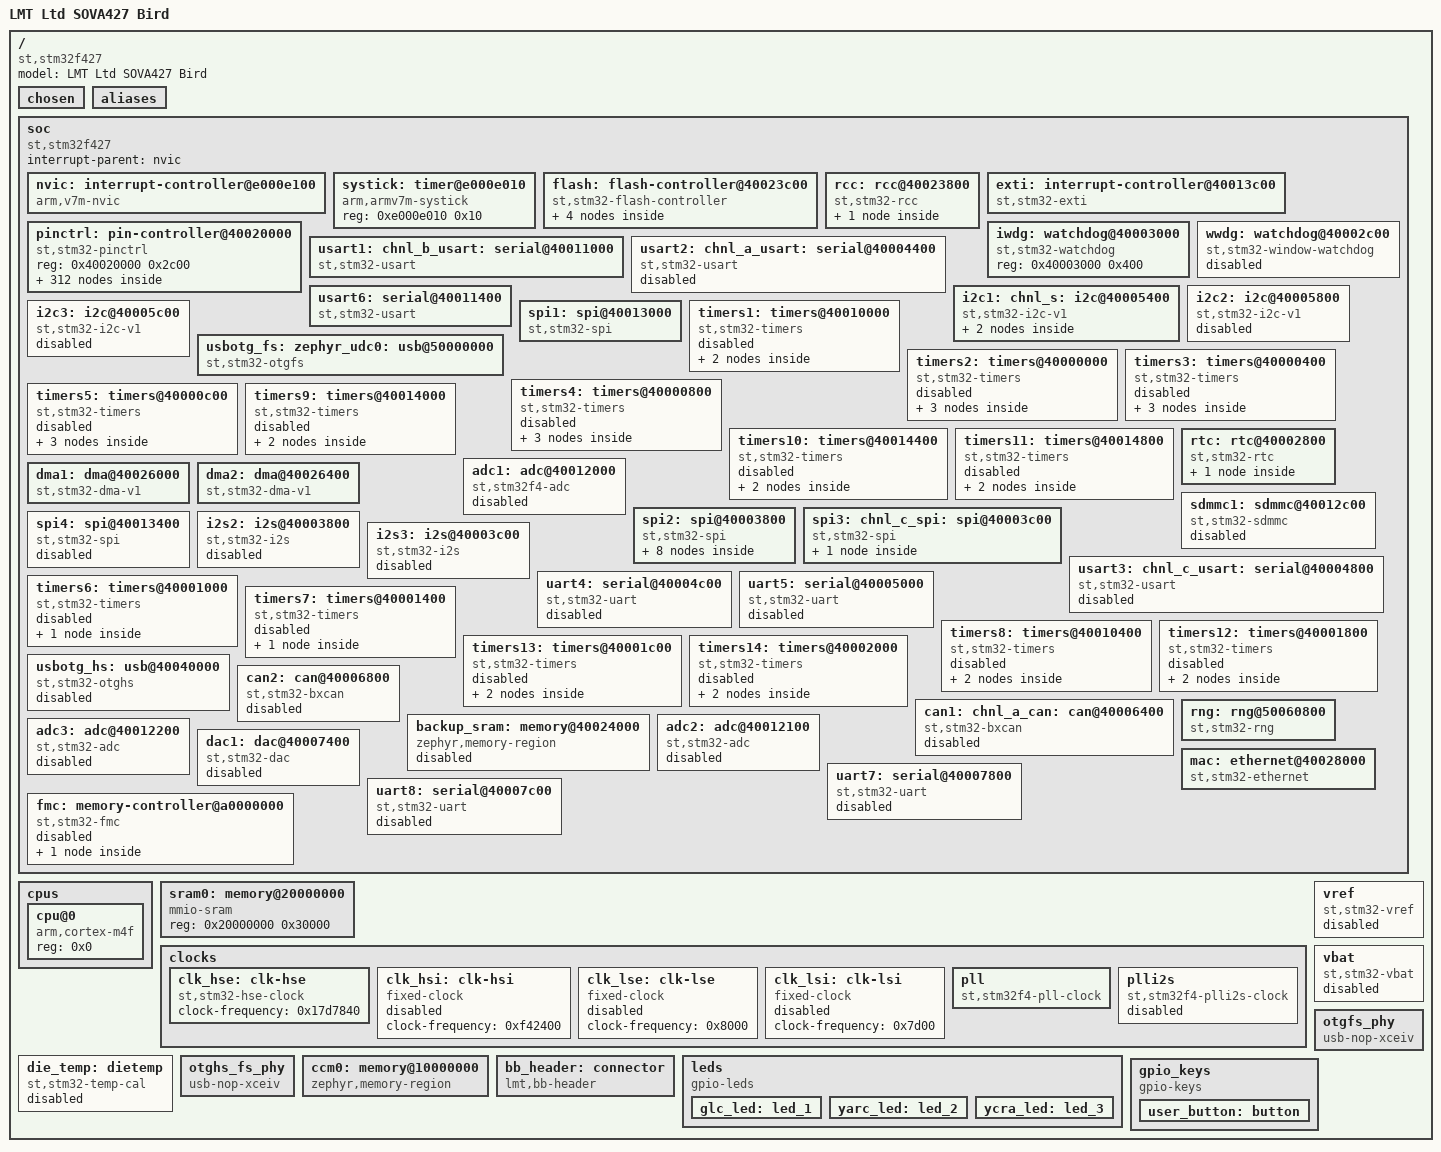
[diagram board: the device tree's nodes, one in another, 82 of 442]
/dts-v1/;

/ {
	#address-cells = < 0x1 >;
	#size-cells = < 0x1 >;
	model = "LMT Ltd SOVA427 Bird";
	compatible = "st,stm32f427";
	chosen {
		zephyr,flash-controller = &flash;
		zephyr,entropy = &rng;
		zephyr,console = &usart6;
		zephyr,shell-uart = &usart6;
		zephyr,uart-mcumgr = &usart6;
		zephyr,sram = &sram0;
		zephyr,ccm = &ccm0;
		zephyr,canbus = &can1;
		zephyr,code-partition = &slot0_partition;
		zephyr,flash = &flash0;
		zephyr,ieee802154 = &spi_cc1200;
	};
	aliases {
		led0 = &glc_led;
		led1 = &yarc_led;
		led2 = &ycra_led;
		sw0 = &user_button;
		bootloader-led0 = &glc_led;
		sdhc0 = &sdhc0;
		ti-cc1200 = &spi_cc1200;
	};
	soc {
		#address-cells = < 0x1 >;
		#size-cells = < 0x1 >;
		compatible = "st,stm32f427", "st,stm32f4", "simple-bus";
		interrupt-parent = < &nvic >;
		ranges;
		nvic: interrupt-controller@e000e100 {
			#address-cells = < 0x1 >;
			compatible = "arm,v7m-nvic";
			reg = < 0xe000e100 0xc00 >;
			interrupt-controller;
			#interrupt-cells = < 0x2 >;
			arm,num-irq-priority-bits = < 0x4 >;
			phandle = < 0x1 >;
		};
		systick: timer@e000e010 {
			compatible = "arm,armv7m-systick";
			reg = < 0xe000e010 0x10 >;
		};
		flash: flash-controller@40023c00 {
			compatible = "st,stm32-flash-controller", "st,stm32f4-flash-controller";
			reg = < 0x40023c00 0x400 >;
			interrupts = < 0x4 0x0 >;
			#address-cells = < 0x1 >;
			#size-cells = < 0x1 >;
			flash0: flash@8000000 {
				compatible = "st,stm32-nv-flash", "soc-nv-flash";
				write-block-size = < 0x1 >;
				max-erase-time = < 0xfa0 >;
				reg = < 0x8000000 0x200000 >;
				partitions {
					compatible = "fixed-partitions";
					#address-cells = < 0x1 >;
					#size-cells = < 0x1 >;
					boot_partition: partition@0 {
						label = "mcuboot";
						reg = < 0x0 0x40000 >;
						read-only;
					};
					slot0_partition: partition@40000 {
						label = "image-0";
						reg = < 0x40000 0x1c0000 >;
					};
				};
			};
		};
		rcc: rcc@40023800 {
			compatible = "st,stm32-rcc";
			#clock-cells = < 0x2 >;
			reg = < 0x40023800 0x400 >;
			clocks = < &pll >;
			clock-frequency = < 0xa037a00 >;
			ahb-prescaler = < 0x1 >;
			apb1-prescaler = < 0x4 >;
			apb2-prescaler = < 0x2 >;
			phandle = < 0x3 >;
			rctl: reset-controller {
				compatible = "st,stm32-rcc-rctl";
				#reset-cells = < 0x1 >;
				phandle = < 0x4 >;
			};
		};
		exti: interrupt-controller@40013c00 {
			compatible = "st,stm32-exti";
			interrupt-controller;
			#interrupt-cells = < 0x1 >;
			#address-cells = < 0x1 >;
			reg = < 0x40013c00 0x400 >;
			num-lines = < 0x10 >;
			interrupts = < 0x6 0x0 >, < 0x7 0x0 >, < 0x8 0x0 >, < 0x9 0x0 >, < 0xa 0x0 >, < 0x17 0x0 >, < 0x28 0x0 >;
			interrupt-names = "line0", "line1", "line2", "line3", "line4", "line5-9", "line10-15";
			line-ranges = < 0x0 0x1 >, < 0x1 0x1 >, < 0x2 0x1 >, < 0x3 0x1 >, < 0x4 0x1 >, < 0x5 0x5 >, < 0xa 0x6 >;
		};
		pinctrl: pin-controller@40020000 {
			compatible = "st,stm32-pinctrl";
			#address-cells = < 0x1 >;
			#size-cells = < 0x1 >;
			reg = < 0x40020000 0x2c00 >;
			gpioa: gpio@40020000 {
				compatible = "st,stm32-gpio";
				gpio-controller;
				#gpio-cells = < 0x2 >;
				reg = < 0x40020000 0x400 >;
				clocks = < &rcc 0x30 0x1 >;
				phandle = < 0x32 >;
			};
			gpiob: gpio@40020400 {
				compatible = "st,stm32-gpio";
				gpio-controller;
				#gpio-cells = < 0x2 >;
				reg = < 0x40020400 0x400 >;
				clocks = < &rcc 0x30 0x2 >;
				phandle = < 0x1e >;
			};
			gpioc: gpio@40020800 {
				compatible = "st,stm32-gpio";
				gpio-controller;
				#gpio-cells = < 0x2 >;
				reg = < 0x40020800 0x400 >;
				clocks = < &rcc 0x30 0x4 >;
				phandle = < 0x31 >;
			};
			gpiod: gpio@40020c00 {
				compatible = "st,stm32-gpio";
				gpio-controller;
				#gpio-cells = < 0x2 >;
				reg = < 0x40020c00 0x400 >;
				clocks = < &rcc 0x30 0x8 >;
				phandle = < 0x1d >;
			};
			gpioe: gpio@40021000 {
				compatible = "st,stm32-gpio";
				gpio-controller;
				#gpio-cells = < 0x2 >;
				reg = < 0x40021000 0x400 >;
				clocks = < &rcc 0x30 0x10 >;
				phandle = < 0x18 >;
			};
			gpiof: gpio@40021400 {
				compatible = "st,stm32-gpio";
				gpio-controller;
				#gpio-cells = < 0x2 >;
				reg = < 0x40021400 0x400 >;
				clocks = < &rcc 0x30 0x20 >;
			};
			gpiog: gpio@40021800 {
				compatible = "st,stm32-gpio";
				gpio-controller;
				#gpio-cells = < 0x2 >;
				reg = < 0x40021800 0x400 >;
				clocks = < &rcc 0x30 0x40 >;
			};
			gpioh: gpio@40021c00 {
				compatible = "st,stm32-gpio";
				gpio-controller;
				#gpio-cells = < 0x2 >;
				reg = < 0x40021c00 0x400 >;
				clocks = < &rcc 0x30 0x80 >;
			};
			gpioi: gpio@40022000 {
				compatible = "st,stm32-gpio";
				gpio-controller;
				#gpio-cells = < 0x2 >;
				reg = < 0x40022000 0x400 >;
				clocks = < &rcc 0x30 0x100 >;
			};
			gpioj: gpio@40022400 {
				compatible = "st,stm32-gpio";
				gpio-controller;
				#gpio-cells = < 0x2 >;
				reg = < 0x40022400 0x400 >;
				clocks = < &rcc 0x30 0x200 >;
			};
			gpiok: gpio@40022800 {
				compatible = "st,stm32-gpio";
				gpio-controller;
				#gpio-cells = < 0x2 >;
				reg = < 0x40022800 0x400 >;
				clocks = < &rcc 0x30 0x400 >;
			};
			adc1_in0_pa0: adc1_in0_pa0 {
				pinmux = < 0x10 >;
			};
			adc1_in1_pa1: adc1_in1_pa1 {
				pinmux = < 0x30 >;
			};
			adc1_in2_pa2: adc1_in2_pa2 {
				pinmux = < 0x50 >;
			};
			adc1_in3_pa3: adc1_in3_pa3 {
				pinmux = < 0x70 >;
			};
			adc1_in4_pa4: adc1_in4_pa4 {
				pinmux = < 0x90 >;
			};
			adc1_in5_pa5: adc1_in5_pa5 {
				pinmux = < 0xb0 >;
			};
			adc1_in6_pa6: adc1_in6_pa6 {
				pinmux = < 0xd0 >;
			};
			adc1_in7_pa7: adc1_in7_pa7 {
				pinmux = < 0xf0 >;
			};
			adc1_in8_pb0: adc1_in8_pb0 {
				pinmux = < 0x210 >;
			};
			adc1_in9_pb1: adc1_in9_pb1 {
				pinmux = < 0x230 >;
			};
			adc1_in10_pc0: adc1_in10_pc0 {
				pinmux = < 0x410 >;
			};
			adc1_in11_pc1: adc1_in11_pc1 {
				pinmux = < 0x430 >;
			};
			adc1_in12_pc2: adc1_in12_pc2 {
				pinmux = < 0x450 >;
			};
			adc1_in13_pc3: adc1_in13_pc3 {
				pinmux = < 0x470 >;
			};
			adc1_in14_pc4: adc1_in14_pc4 {
				pinmux = < 0x490 >;
			};
			adc1_in15_pc5: adc1_in15_pc5 {
				pinmux = < 0x4b0 >;
			};
			adc2_in0_pa0: adc2_in0_pa0 {
				pinmux = < 0x10 >;
			};
			adc2_in1_pa1: adc2_in1_pa1 {
				pinmux = < 0x30 >;
			};
			adc2_in2_pa2: adc2_in2_pa2 {
				pinmux = < 0x50 >;
			};
			adc2_in3_pa3: adc2_in3_pa3 {
				pinmux = < 0x70 >;
			};
			adc2_in4_pa4: adc2_in4_pa4 {
				pinmux = < 0x90 >;
			};
			adc2_in5_pa5: adc2_in5_pa5 {
				pinmux = < 0xb0 >;
			};
			adc2_in6_pa6: adc2_in6_pa6 {
				pinmux = < 0xd0 >;
			};
			adc2_in7_pa7: adc2_in7_pa7 {
				pinmux = < 0xf0 >;
			};
			adc2_in8_pb0: adc2_in8_pb0 {
				pinmux = < 0x210 >;
			};
			adc2_in9_pb1: adc2_in9_pb1 {
				pinmux = < 0x230 >;
			};
			adc2_in10_pc0: adc2_in10_pc0 {
				pinmux = < 0x410 >;
			};
			adc2_in11_pc1: adc2_in11_pc1 {
				pinmux = < 0x430 >;
			};
			adc2_in12_pc2: adc2_in12_pc2 {
				pinmux = < 0x450 >;
			};
			adc2_in13_pc3: adc2_in13_pc3 {
				pinmux = < 0x470 >;
			};
			adc2_in14_pc4: adc2_in14_pc4 {
				pinmux = < 0x490 >;
			};
			adc2_in15_pc5: adc2_in15_pc5 {
				pinmux = < 0x4b0 >;
			};
			adc3_in0_pa0: adc3_in0_pa0 {
				pinmux = < 0x10 >;
			};
			adc3_in1_pa1: adc3_in1_pa1 {
				pinmux = < 0x30 >;
			};
			adc3_in2_pa2: adc3_in2_pa2 {
				pinmux = < 0x50 >;
			};
			adc3_in3_pa3: adc3_in3_pa3 {
				pinmux = < 0x70 >;
			};
			adc3_in10_pc0: adc3_in10_pc0 {
				pinmux = < 0x410 >;
			};
			adc3_in11_pc1: adc3_in11_pc1 {
				pinmux = < 0x430 >;
			};
			adc3_in12_pc2: adc3_in12_pc2 {
				pinmux = < 0x450 >;
			};
			adc3_in13_pc3: adc3_in13_pc3 {
				pinmux = < 0x470 >;
			};
			can1_rx_pa11: can1_rx_pa11 {
				pinmux = < 0x169 >;
				bias-pull-up;
			};
			can1_rx_pb8: can1_rx_pb8 {
				pinmux = < 0x309 >;
				bias-pull-up;
			};
			can1_rx_pd0: can1_rx_pd0 {
				pinmux = < 0x609 >;
				bias-pull-up;
				phandle = < 0x24 >;
			};
			can2_rx_pb5: can2_rx_pb5 {
				pinmux = < 0x2a9 >;
				bias-pull-up;
			};
			can2_rx_pb12: can2_rx_pb12 {
				pinmux = < 0x389 >;
				bias-pull-up;
			};
			can1_tx_pa12: can1_tx_pa12 {
				pinmux = < 0x189 >;
			};
			can1_tx_pb9: can1_tx_pb9 {
				pinmux = < 0x329 >;
			};
			can1_tx_pd1: can1_tx_pd1 {
				pinmux = < 0x629 >;
				phandle = < 0x25 >;
			};
			can2_tx_pb6: can2_tx_pb6 {
				pinmux = < 0x2c9 >;
			};
			can2_tx_pb13: can2_tx_pb13 {
				pinmux = < 0x3a9 >;
			};
			dac_out1_pa4: dac_out1_pa4 {
				pinmux = < 0x90 >;
			};
			dac_out2_pa5: dac_out2_pa5 {
				pinmux = < 0xb0 >;
			};
			eth_col_pa3: eth_col_pa3 {
				pinmux = < 0x6b >;
				slew-rate = "very-high-speed";
			};
			eth_crs_pa0: eth_crs_pa0 {
				pinmux = < 0xb >;
				slew-rate = "very-high-speed";
			};
			eth_crs_dv_pa7: eth_crs_dv_pa7 {
				pinmux = < 0xeb >;
				slew-rate = "very-high-speed";
				phandle = < 0x2b >;
			};
			eth_mdc_pc1: eth_mdc_pc1 {
				pinmux = < 0x42b >;
				slew-rate = "very-high-speed";
				phandle = < 0x26 >;
			};
			eth_mdio_pa2: eth_mdio_pa2 {
				pinmux = < 0x4b >;
				slew-rate = "very-high-speed";
				phandle = < 0x2a >;
			};
			eth_pps_out_pb5: eth_pps_out_pb5 {
				pinmux = < 0x2ab >;
				slew-rate = "very-high-speed";
			};
			eth_ref_clk_pa1: eth_ref_clk_pa1 {
				pinmux = < 0x2b >;
				slew-rate = "very-high-speed";
				phandle = < 0x29 >;
			};
			eth_rxd0_pc4: eth_rxd0_pc4 {
				pinmux = < 0x48b >;
				slew-rate = "very-high-speed";
				phandle = < 0x27 >;
			};
			eth_rxd1_pc5: eth_rxd1_pc5 {
				pinmux = < 0x4ab >;
				slew-rate = "very-high-speed";
				phandle = < 0x28 >;
			};
			eth_rxd2_pb0: eth_rxd2_pb0 {
				pinmux = < 0x20b >;
				slew-rate = "very-high-speed";
			};
			eth_rxd3_pb1: eth_rxd3_pb1 {
				pinmux = < 0x22b >;
				slew-rate = "very-high-speed";
			};
			eth_rx_clk_pa1: eth_rx_clk_pa1 {
				pinmux = < 0x2b >;
				slew-rate = "very-high-speed";
			};
			eth_rx_dv_pa7: eth_rx_dv_pa7 {
				pinmux = < 0xeb >;
				slew-rate = "very-high-speed";
			};
			eth_rx_er_pb10: eth_rx_er_pb10 {
				pinmux = < 0x34b >;
				slew-rate = "very-high-speed";
			};
			eth_txd0_pb12: eth_txd0_pb12 {
				pinmux = < 0x38b >;
				slew-rate = "very-high-speed";
				phandle = < 0x2d >;
			};
			eth_txd1_pb13: eth_txd1_pb13 {
				pinmux = < 0x3ab >;
				slew-rate = "very-high-speed";
				phandle = < 0x2e >;
			};
			eth_txd2_pc2: eth_txd2_pc2 {
				pinmux = < 0x44b >;
				slew-rate = "very-high-speed";
			};
			eth_txd3_pb8: eth_txd3_pb8 {
				pinmux = < 0x30b >;
				slew-rate = "very-high-speed";
			};
			eth_txd3_pe2: eth_txd3_pe2 {
				pinmux = < 0x84b >;
				slew-rate = "very-high-speed";
			};
			eth_tx_clk_pc3: eth_tx_clk_pc3 {
				pinmux = < 0x46b >;
				slew-rate = "very-high-speed";
			};
			eth_tx_en_pb11: eth_tx_en_pb11 {
				pinmux = < 0x36b >;
				slew-rate = "very-high-speed";
				phandle = < 0x2c >;
			};
			fmc_sdcke1_pb5: fmc_sdcke1_pb5 {
				pinmux = < 0x2ac >;
				bias-pull-up;
				slew-rate = "very-high-speed";
			};
			fmc_sdne1_pb6: fmc_sdne1_pb6 {
				pinmux = < 0x2cc >;
				bias-pull-up;
				slew-rate = "very-high-speed";
			};
			fmc_nl_pb7: fmc_nl_pb7 {
				pinmux = < 0x2ec >;
				bias-pull-up;
				slew-rate = "very-high-speed";
			};
			fmc_sdnwe_pc0: fmc_sdnwe_pc0 {
				pinmux = < 0x40c >;
				bias-pull-up;
				slew-rate = "very-high-speed";
			};
			fmc_sdne0_pc2: fmc_sdne0_pc2 {
				pinmux = < 0x44c >;
				bias-pull-up;
				slew-rate = "very-high-speed";
			};
			fmc_sdcke0_pc3: fmc_sdcke0_pc3 {
				pinmux = < 0x46c >;
				bias-pull-up;
				slew-rate = "very-high-speed";
			};
			fmc_d2_pd0: fmc_d2_pd0 {
				pinmux = < 0x60c >;
				bias-pull-up;
				slew-rate = "very-high-speed";
			};
			fmc_d3_pd1: fmc_d3_pd1 {
				pinmux = < 0x62c >;
				bias-pull-up;
				slew-rate = "very-high-speed";
			};
			fmc_clk_pd3: fmc_clk_pd3 {
				pinmux = < 0x66c >;
				bias-pull-up;
				slew-rate = "very-high-speed";
			};
			fmc_noe_pd4: fmc_noe_pd4 {
				pinmux = < 0x68c >;
				bias-pull-up;
				slew-rate = "very-high-speed";
			};
			fmc_nwe_pd5: fmc_nwe_pd5 {
				pinmux = < 0x6ac >;
				bias-pull-up;
				slew-rate = "very-high-speed";
			};
			fmc_nwait_pd6: fmc_nwait_pd6 {
				pinmux = < 0x6cc >;
				bias-pull-up;
				slew-rate = "very-high-speed";
			};
			fmc_ne1_pd7: fmc_ne1_pd7 {
				pinmux = < 0x6ec >;
				bias-pull-up;
				slew-rate = "very-high-speed";
			};
			fmc_d13_pd8: fmc_d13_pd8 {
				pinmux = < 0x70c >;
				bias-pull-up;
				slew-rate = "very-high-speed";
			};
			fmc_d14_pd9: fmc_d14_pd9 {
				pinmux = < 0x72c >;
				bias-pull-up;
				slew-rate = "very-high-speed";
			};
			fmc_d15_pd10: fmc_d15_pd10 {
				pinmux = < 0x74c >;
				bias-pull-up;
				slew-rate = "very-high-speed";
			};
			fmc_a16_pd11: fmc_a16_pd11 {
				pinmux = < 0x76c >;
				bias-pull-up;
				slew-rate = "very-high-speed";
			};
			fmc_a17_pd12: fmc_a17_pd12 {
				pinmux = < 0x78c >;
				bias-pull-up;
				slew-rate = "very-high-speed";
			};
			fmc_a18_pd13: fmc_a18_pd13 {
				pinmux = < 0x7ac >;
				bias-pull-up;
				slew-rate = "very-high-speed";
			};
			fmc_d0_pd14: fmc_d0_pd14 {
				pinmux = < 0x7cc >;
				bias-pull-up;
				slew-rate = "very-high-speed";
			};
			fmc_d1_pd15: fmc_d1_pd15 {
				pinmux = < 0x7ec >;
				bias-pull-up;
				slew-rate = "very-high-speed";
			};
			fmc_nbl0_pe0: fmc_nbl0_pe0 {
				pinmux = < 0x80c >;
				bias-pull-up;
				slew-rate = "very-high-speed";
			};
			fmc_nbl1_pe1: fmc_nbl1_pe1 {
				pinmux = < 0x82c >;
				bias-pull-up;
				slew-rate = "very-high-speed";
			};
			fmc_a23_pe2: fmc_a23_pe2 {
				pinmux = < 0x84c >;
				bias-pull-up;
				slew-rate = "very-high-speed";
			};
			fmc_a19_pe3: fmc_a19_pe3 {
				pinmux = < 0x86c >;
				bias-pull-up;
				slew-rate = "very-high-speed";
			};
			fmc_a20_pe4: fmc_a20_pe4 {
				pinmux = < 0x88c >;
				bias-pull-up;
				slew-rate = "very-high-speed";
			};
			fmc_a21_pe5: fmc_a21_pe5 {
				pinmux = < 0x8ac >;
				bias-pull-up;
				slew-rate = "very-high-speed";
			};
			fmc_a22_pe6: fmc_a22_pe6 {
				pinmux = < 0x8cc >;
				bias-pull-up;
				slew-rate = "very-high-speed";
			};
			fmc_d4_pe7: fmc_d4_pe7 {
				pinmux = < 0x8ec >;
				bias-pull-up;
				slew-rate = "very-high-speed";
			};
			fmc_d5_pe8: fmc_d5_pe8 {
				pinmux = < 0x90c >;
				bias-pull-up;
				slew-rate = "very-high-speed";
			};
			fmc_d6_pe9: fmc_d6_pe9 {
				pinmux = < 0x92c >;
				bias-pull-up;
				slew-rate = "very-high-speed";
			};
			fmc_d7_pe10: fmc_d7_pe10 {
				pinmux = < 0x94c >;
				bias-pull-up;
				slew-rate = "very-high-speed";
			};
			fmc_d8_pe11: fmc_d8_pe11 {
				pinmux = < 0x96c >;
				bias-pull-up;
				slew-rate = "very-high-speed";
			};
			fmc_d9_pe12: fmc_d9_pe12 {
				pinmux = < 0x98c >;
				bias-pull-up;
				slew-rate = "very-high-speed";
			};
			fmc_d10_pe13: fmc_d10_pe13 {
				pinmux = < 0x9ac >;
				bias-pull-up;
				slew-rate = "very-high-speed";
			};
			fmc_d11_pe14: fmc_d11_pe14 {
				pinmux = < 0x9cc >;
				bias-pull-up;
				slew-rate = "very-high-speed";
			};
			fmc_d12_pe15: fmc_d12_pe15 {
				pinmux = < 0x9ec >;
				bias-pull-up;
				slew-rate = "very-high-speed";
			};
			i2c1_scl_pb6: i2c1_scl_pb6 {
				pinmux = < 0x2c4 >;
				bias-pull-up;
				drive-open-drain;
			};
			i2c1_scl_pb8: i2c1_scl_pb8 {
				pinmux = < 0x304 >;
				bias-pull-up;
				drive-open-drain;
				phandle = < 0xd >;
			};
			i2c2_scl_pb10: i2c2_scl_pb10 {
				pinmux = < 0x344 >;
				bias-pull-up;
				drive-open-drain;
			};
			i2c3_scl_pa8: i2c3_scl_pa8 {
				pinmux = < 0x104 >;
				bias-pull-up;
				drive-open-drain;
			};
			i2c1_sda_pb7: i2c1_sda_pb7 {
				pinmux = < 0x2e4 >;
				bias-pull-up;
				drive-open-drain;
			};
			i2c1_sda_pb9: i2c1_sda_pb9 {
				pinmux = < 0x324 >;
				bias-pull-up;
				drive-open-drain;
				phandle = < 0xe >;
			};
			i2c2_sda_pb11: i2c2_sda_pb11 {
				pinmux = < 0x364 >;
				bias-pull-up;
				drive-open-drain;
			};
			i2c3_sda_pc9: i2c3_sda_pc9 {
				pinmux = < 0x524 >;
				bias-pull-up;
				drive-open-drain;
			};
			i2s2_ck_pb10: i2s2_ck_pb10 {
				pinmux = < 0x345 >;
				slew-rate = "very-high-speed";
			};
			i2s2_ck_pb13: i2s2_ck_pb13 {
				pinmux = < 0x3a5 >;
				slew-rate = "very-high-speed";
			};
			i2s2_ck_pd3: i2s2_ck_pd3 {
				pinmux = < 0x665 >;
				slew-rate = "very-high-speed";
			};
			i2s3_ck_pb3: i2s3_ck_pb3 {
				pinmux = < 0x266 >;
				slew-rate = "very-high-speed";
			};
			i2s3_ck_pc10: i2s3_ck_pc10 {
				pinmux = < 0x546 >;
				slew-rate = "very-high-speed";
			};
			i2s2_sd_pb15: i2s2_sd_pb15 {
				pinmux = < 0x3e5 >;
			};
			i2s2_sd_pc3: i2s2_sd_pc3 {
				pinmux = < 0x465 >;
			};
			i2s3_sd_pb5: i2s3_sd_pb5 {
				pinmux = < 0x2a6 >;
			};
			i2s3_sd_pc12: i2s3_sd_pc12 {
				pinmux = < 0x586 >;
			};
			i2s3_sd_pd6: i2s3_sd_pd6 {
				pinmux = < 0x6c5 >;
			};
			i2s2_ws_pb9: i2s2_ws_pb9 {
				pinmux = < 0x325 >;
			};
			i2s2_ws_pb12: i2s2_ws_pb12 {
				pinmux = < 0x385 >;
			};
			i2s3_ws_pa4: i2s3_ws_pa4 {
				pinmux = < 0x86 >;
			};
			i2s3_ws_pa15: i2s3_ws_pa15 {
				pinmux = < 0x1e6 >;
			};
			sdio_d4_pb8: sdio_d4_pb8 {
				pinmux = < 0x30c >;
				bias-pull-up;
				slew-rate = "very-high-speed";
			};
			sdio_d5_pb9: sdio_d5_pb9 {
				pinmux = < 0x32c >;
				bias-pull-up;
				slew-rate = "very-high-speed";
			};
			sdio_d6_pc6: sdio_d6_pc6 {
				pinmux = < 0x4cc >;
				bias-pull-up;
				slew-rate = "very-high-speed";
			};
			sdio_d7_pc7: sdio_d7_pc7 {
				pinmux = < 0x4ec >;
				bias-pull-up;
				slew-rate = "very-high-speed";
			};
			sdio_d0_pc8: sdio_d0_pc8 {
				pinmux = < 0x50c >;
				bias-pull-up;
				slew-rate = "very-high-speed";
			};
			sdio_d1_pc9: sdio_d1_pc9 {
				pinmux = < 0x52c >;
				bias-pull-up;
				slew-rate = "very-high-speed";
			};
			sdio_d2_pc10: sdio_d2_pc10 {
				pinmux = < 0x54c >;
				bias-pull-up;
				slew-rate = "very-high-speed";
			};
			sdio_d3_pc11: sdio_d3_pc11 {
				pinmux = < 0x56c >;
				bias-pull-up;
				slew-rate = "very-high-speed";
			};
			sdio_ck_pc12: sdio_ck_pc12 {
				pinmux = < 0x58c >;
				bias-pull-up;
				slew-rate = "very-high-speed";
			};
			sdio_cmd_pd2: sdio_cmd_pd2 {
				pinmux = < 0x64c >;
				bias-pull-up;
				slew-rate = "very-high-speed";
			};
			spi1_miso_pa6: spi1_miso_pa6 {
				pinmux = < 0xc5 >;
				bias-pull-down;
				phandle = < 0x10 >;
			};
			spi1_miso_pb4: spi1_miso_pb4 {
				pinmux = < 0x285 >;
				bias-pull-down;
			};
			spi2_miso_pb14: spi2_miso_pb14 {
				pinmux = < 0x3c5 >;
				bias-pull-down;
				phandle = < 0x16 >;
			};
			spi2_miso_pc2: spi2_miso_pc2 {
				pinmux = < 0x445 >;
				bias-pull-down;
			};
			spi3_miso_pb4: spi3_miso_pb4 {
				pinmux = < 0x286 >;
				bias-pull-down;
			};
			spi3_miso_pc11: spi3_miso_pc11 {
				pinmux = < 0x566 >;
				bias-pull-down;
				phandle = < 0x1a >;
			};
			spi4_miso_pe5: spi4_miso_pe5 {
				pinmux = < 0x8a5 >;
				bias-pull-down;
			};
			spi4_miso_pe13: spi4_miso_pe13 {
				pinmux = < 0x9a5 >;
				bias-pull-down;
			};
			spi1_mosi_pa7: spi1_mosi_pa7 {
				pinmux = < 0xe5 >;
				bias-pull-down;
				phandle = < 0x11 >;
			};
			spi1_mosi_pb5: spi1_mosi_pb5 {
				pinmux = < 0x2a5 >;
				bias-pull-down;
			};
			spi2_mosi_pb15: spi2_mosi_pb15 {
				pinmux = < 0x3e5 >;
				bias-pull-down;
				phandle = < 0x17 >;
			};
			spi2_mosi_pc3: spi2_mosi_pc3 {
				pinmux = < 0x465 >;
				bias-pull-down;
			};
			spi3_mosi_pb5: spi3_mosi_pb5 {
				pinmux = < 0x2a6 >;
				bias-pull-down;
			};
			spi3_mosi_pc12: spi3_mosi_pc12 {
				pinmux = < 0x586 >;
				bias-pull-down;
				phandle = < 0x1b >;
			};
			spi3_mosi_pd6: spi3_mosi_pd6 {
				pinmux = < 0x6c5 >;
				bias-pull-down;
			};
			spi4_mosi_pe6: spi4_mosi_pe6 {
				pinmux = < 0x8c5 >;
				bias-pull-down;
			};
			spi4_mosi_pe14: spi4_mosi_pe14 {
				pinmux = < 0x9c5 >;
				bias-pull-down;
			};
			spi1_nss_pa4: spi1_nss_pa4 {
				pinmux = < 0x85 >;
				bias-pull-up;
			};
			spi1_nss_pa15: spi1_nss_pa15 {
				pinmux = < 0x1e5 >;
				bias-pull-up;
			};
			spi2_nss_pb9: spi2_nss_pb9 {
				pinmux = < 0x325 >;
				bias-pull-up;
			};
			spi2_nss_pb12: spi2_nss_pb12 {
				pinmux = < 0x385 >;
				bias-pull-up;
			};
			spi3_nss_pa4: spi3_nss_pa4 {
				pinmux = < 0x86 >;
				bias-pull-up;
			};
			spi3_nss_pa15: spi3_nss_pa15 {
				pinmux = < 0x1e6 >;
				bias-pull-up;
			};
			spi4_nss_pe4: spi4_nss_pe4 {
				pinmux = < 0x885 >;
				bias-pull-up;
			};
			spi4_nss_pe11: spi4_nss_pe11 {
				pinmux = < 0x965 >;
				bias-pull-up;
			};
			spi1_sck_pa5: spi1_sck_pa5 {
				pinmux = < 0xa5 >;
				bias-pull-down;
				slew-rate = "very-high-speed";
				phandle = < 0xf >;
			};
			spi1_sck_pb3: spi1_sck_pb3 {
				pinmux = < 0x265 >;
				bias-pull-down;
				slew-rate = "very-high-speed";
			};
			spi2_sck_pb10: spi2_sck_pb10 {
				pinmux = < 0x345 >;
				bias-pull-down;
				slew-rate = "very-high-speed";
				phandle = < 0x15 >;
			};
			spi2_sck_pb13: spi2_sck_pb13 {
				pinmux = < 0x3a5 >;
				bias-pull-down;
				slew-rate = "very-high-speed";
			};
			spi2_sck_pd3: spi2_sck_pd3 {
				pinmux = < 0x665 >;
				bias-pull-down;
				slew-rate = "very-high-speed";
			};
			spi3_sck_pb3: spi3_sck_pb3 {
				pinmux = < 0x266 >;
				bias-pull-down;
				slew-rate = "very-high-speed";
			};
			spi3_sck_pc10: spi3_sck_pc10 {
				pinmux = < 0x546 >;
				bias-pull-down;
				slew-rate = "very-high-speed";
				phandle = < 0x19 >;
			};
			spi4_sck_pe2: spi4_sck_pe2 {
				pinmux = < 0x845 >;
				bias-pull-down;
				slew-rate = "very-high-speed";
			};
			spi4_sck_pe12: spi4_sck_pe12 {
				pinmux = < 0x985 >;
				bias-pull-down;
				slew-rate = "very-high-speed";
			};
			tim10_ch1_pb8: tim10_ch1_pb8 {
				pinmux = < 0x303 >;
			};
			tim1_ch1n_pa7: tim1_ch1n_pa7 {
				pinmux = < 0xe1 >;
			};
			tim1_ch1_pa8: tim1_ch1_pa8 {
				pinmux = < 0x101 >;
			};
			tim1_ch2_pa9: tim1_ch2_pa9 {
				pinmux = < 0x121 >;
			};
			tim1_ch3_pa10: tim1_ch3_pa10 {
				pinmux = < 0x141 >;
			};
			tim1_ch4_pa11: tim1_ch4_pa11 {
				pinmux = < 0x161 >;
			};
			tim1_ch2n_pb0: tim1_ch2n_pb0 {
				pinmux = < 0x201 >;
			};
			tim1_ch3n_pb1: tim1_ch3n_pb1 {
				pinmux = < 0x221 >;
			};
			tim11_ch1_pb9: tim11_ch1_pb9 {
				pinmux = < 0x323 >;
			};
			tim1_ch1n_pb13: tim1_ch1n_pb13 {
				pinmux = < 0x3a1 >;
			};
			tim1_ch2n_pb14: tim1_ch2n_pb14 {
				pinmux = < 0x3c1 >;
			};
			tim1_ch3n_pb15: tim1_ch3n_pb15 {
				pinmux = < 0x3e1 >;
			};
			tim1_ch1n_pe8: tim1_ch1n_pe8 {
				pinmux = < 0x901 >;
			};
			tim1_ch1_pe9: tim1_ch1_pe9 {
				pinmux = < 0x921 >;
			};
			tim1_ch2n_pe10: tim1_ch2n_pe10 {
				pinmux = < 0x941 >;
			};
			tim1_ch2_pe11: tim1_ch2_pe11 {
				pinmux = < 0x961 >;
			};
			tim1_ch3n_pe12: tim1_ch3n_pe12 {
				pinmux = < 0x981 >;
			};
			tim1_ch3_pe13: tim1_ch3_pe13 {
				pinmux = < 0x9a1 >;
			};
			tim1_ch4_pe14: tim1_ch4_pe14 {
				pinmux = < 0x9c1 >;
			};
			tim2_ch1_pa0: tim2_ch1_pa0 {
				pinmux = < 0x1 >;
			};
			tim2_ch2_pa1: tim2_ch2_pa1 {
				pinmux = < 0x21 >;
			};
			tim2_ch3_pa2: tim2_ch3_pa2 {
				pinmux = < 0x41 >;
			};
			tim2_ch4_pa3: tim2_ch4_pa3 {
				pinmux = < 0x61 >;
			};
			tim2_ch1_pa5: tim2_ch1_pa5 {
				pinmux = < 0xa1 >;
			};
			tim2_ch1_pa15: tim2_ch1_pa15 {
				pinmux = < 0x1e1 >;
			};
			tim2_ch2_pb3: tim2_ch2_pb3 {
				pinmux = < 0x261 >;
			};
			tim2_ch3_pb10: tim2_ch3_pb10 {
				pinmux = < 0x341 >;
			};
			tim2_ch4_pb11: tim2_ch4_pb11 {
				pinmux = < 0x361 >;
			};
			tim12_ch1_pb14: tim12_ch1_pb14 {
				pinmux = < 0x3c9 >;
			};
			tim12_ch2_pb15: tim12_ch2_pb15 {
				pinmux = < 0x3e9 >;
			};
			tim13_ch1_pa6: tim13_ch1_pa6 {
				pinmux = < 0xc9 >;
			};
			tim3_ch1_pa6: tim3_ch1_pa6 {
				pinmux = < 0xc2 >;
			};
			tim3_ch2_pa7: tim3_ch2_pa7 {
				pinmux = < 0xe2 >;
			};
			tim3_ch3_pb0: tim3_ch3_pb0 {
				pinmux = < 0x202 >;
			};
			tim3_ch4_pb1: tim3_ch4_pb1 {
				pinmux = < 0x222 >;
			};
			tim3_ch1_pb4: tim3_ch1_pb4 {
				pinmux = < 0x282 >;
			};
			tim3_ch2_pb5: tim3_ch2_pb5 {
				pinmux = < 0x2a2 >;
			};
			tim3_ch1_pc6: tim3_ch1_pc6 {
				pinmux = < 0x4c2 >;
			};
			tim3_ch2_pc7: tim3_ch2_pc7 {
				pinmux = < 0x4e2 >;
			};
			tim3_ch3_pc8: tim3_ch3_pc8 {
				pinmux = < 0x502 >;
			};
			tim3_ch4_pc9: tim3_ch4_pc9 {
				pinmux = < 0x522 >;
			};
			tim14_ch1_pa7: tim14_ch1_pa7 {
				pinmux = < 0xe9 >;
			};
			tim4_ch1_pb6: tim4_ch1_pb6 {
				pinmux = < 0x2c2 >;
			};
			tim4_ch2_pb7: tim4_ch2_pb7 {
				pinmux = < 0x2e2 >;
			};
			tim4_ch3_pb8: tim4_ch3_pb8 {
				pinmux = < 0x302 >;
			};
			tim4_ch4_pb9: tim4_ch4_pb9 {
				pinmux = < 0x322 >;
			};
			tim4_ch1_pd12: tim4_ch1_pd12 {
				pinmux = < 0x782 >;
			};
			tim4_ch2_pd13: tim4_ch2_pd13 {
				pinmux = < 0x7a2 >;
			};
			tim4_ch3_pd14: tim4_ch3_pd14 {
				pinmux = < 0x7c2 >;
			};
			tim4_ch4_pd15: tim4_ch4_pd15 {
				pinmux = < 0x7e2 >;
			};
			tim5_ch1_pa0: tim5_ch1_pa0 {
				pinmux = < 0x2 >;
			};
			tim5_ch2_pa1: tim5_ch2_pa1 {
				pinmux = < 0x22 >;
			};
			tim5_ch3_pa2: tim5_ch3_pa2 {
				pinmux = < 0x42 >;
			};
			tim5_ch4_pa3: tim5_ch4_pa3 {
				pinmux = < 0x62 >;
			};
			tim8_ch1n_pa5: tim8_ch1n_pa5 {
				pinmux = < 0xa3 >;
			};
			tim8_ch1n_pa7: tim8_ch1n_pa7 {
				pinmux = < 0xe3 >;
			};
			tim8_ch2n_pb0: tim8_ch2n_pb0 {
				pinmux = < 0x203 >;
			};
			tim8_ch3n_pb1: tim8_ch3n_pb1 {
				pinmux = < 0x223 >;
			};
			tim8_ch2n_pb14: tim8_ch2n_pb14 {
				pinmux = < 0x3c3 >;
			};
			tim8_ch3n_pb15: tim8_ch3n_pb15 {
				pinmux = < 0x3e3 >;
			};
			tim8_ch1_pc6: tim8_ch1_pc6 {
				pinmux = < 0x4c3 >;
			};
			tim8_ch2_pc7: tim8_ch2_pc7 {
				pinmux = < 0x4e3 >;
			};
			tim8_ch3_pc8: tim8_ch3_pc8 {
				pinmux = < 0x503 >;
			};
			tim8_ch4_pc9: tim8_ch4_pc9 {
				pinmux = < 0x523 >;
			};
			tim9_ch1_pa2: tim9_ch1_pa2 {
				pinmux = < 0x43 >;
			};
			tim9_ch2_pa3: tim9_ch2_pa3 {
				pinmux = < 0x63 >;
			};
			tim9_ch1_pe5: tim9_ch1_pe5 {
				pinmux = < 0x8a3 >;
			};
			tim9_ch2_pe6: tim9_ch2_pe6 {
				pinmux = < 0x8c3 >;
			};
			usart1_cts_pa11: usart1_cts_pa11 {
				pinmux = < 0x167 >;
				bias-pull-up;
				drive-open-drain;
			};
			usart2_cts_pa0: usart2_cts_pa0 {
				pinmux = < 0x7 >;
				bias-pull-up;
				drive-open-drain;
			};
			usart2_cts_pd3: usart2_cts_pd3 {
				pinmux = < 0x667 >;
				bias-pull-up;
				drive-open-drain;
				phandle = < 0xa >;
			};
			usart3_cts_pb13: usart3_cts_pb13 {
				pinmux = < 0x3a7 >;
				bias-pull-up;
				drive-open-drain;
			};
			usart3_cts_pd11: usart3_cts_pd11 {
				pinmux = < 0x767 >;
				bias-pull-up;
				drive-open-drain;
				phandle = < 0x22 >;
			};
			usart1_rts_pa12: usart1_rts_pa12 {
				pinmux = < 0x187 >;
				bias-pull-up;
				drive-open-drain;
			};
			usart2_rts_pa1: usart2_rts_pa1 {
				pinmux = < 0x27 >;
				bias-pull-up;
				drive-open-drain;
			};
			usart2_rts_pd4: usart2_rts_pd4 {
				pinmux = < 0x687 >;
				bias-pull-up;
				drive-open-drain;
				phandle = < 0x9 >;
			};
			usart3_rts_pb14: usart3_rts_pb14 {
				pinmux = < 0x3c7 >;
				bias-pull-up;
				drive-open-drain;
			};
			usart3_rts_pd12: usart3_rts_pd12 {
				pinmux = < 0x787 >;
				bias-pull-up;
				drive-open-drain;
				phandle = < 0x21 >;
			};
			usart1_rx_pa10: usart1_rx_pa10 {
				pinmux = < 0x147 >;
			};
			usart1_rx_pb7: usart1_rx_pb7 {
				pinmux = < 0x2e7 >;
				phandle = < 0x6 >;
			};
			usart2_rx_pa3: usart2_rx_pa3 {
				pinmux = < 0x67 >;
			};
			usart2_rx_pd6: usart2_rx_pd6 {
				pinmux = < 0x6c7 >;
				phandle = < 0x8 >;
			};
			usart3_rx_pb11: usart3_rx_pb11 {
				pinmux = < 0x367 >;
			};
			usart3_rx_pc11: usart3_rx_pc11 {
				pinmux = < 0x567 >;
			};
			usart3_rx_pd9: usart3_rx_pd9 {
				pinmux = < 0x727 >;
				phandle = < 0x20 >;
			};
			uart4_rx_pa1: uart4_rx_pa1 {
				pinmux = < 0x28 >;
			};
			uart4_rx_pc11: uart4_rx_pc11 {
				pinmux = < 0x568 >;
			};
			uart5_rx_pd2: uart5_rx_pd2 {
				pinmux = < 0x648 >;
			};
			usart6_rx_pc7: usart6_rx_pc7 {
				pinmux = < 0x4e8 >;
				phandle = < 0xc >;
			};
			uart7_rx_pe7: uart7_rx_pe7 {
				pinmux = < 0x8e8 >;
			};
			uart8_rx_pe0: uart8_rx_pe0 {
				pinmux = < 0x808 >;
			};
			usart1_tx_pa9: usart1_tx_pa9 {
				pinmux = < 0x127 >;
				bias-pull-up;
			};
			usart1_tx_pb6: usart1_tx_pb6 {
				pinmux = < 0x2c7 >;
				bias-pull-up;
				phandle = < 0x5 >;
			};
			usart2_tx_pa2: usart2_tx_pa2 {
				pinmux = < 0x47 >;
				bias-pull-up;
			};
			usart2_tx_pd5: usart2_tx_pd5 {
				pinmux = < 0x6a7 >;
				bias-pull-up;
				phandle = < 0x7 >;
			};
			usart3_tx_pb10: usart3_tx_pb10 {
				pinmux = < 0x347 >;
				bias-pull-up;
			};
			usart3_tx_pc10: usart3_tx_pc10 {
				pinmux = < 0x547 >;
				bias-pull-up;
			};
			usart3_tx_pd8: usart3_tx_pd8 {
				pinmux = < 0x707 >;
				bias-pull-up;
				phandle = < 0x1f >;
			};
			uart4_tx_pa0: uart4_tx_pa0 {
				pinmux = < 0x8 >;
				bias-pull-up;
			};
			uart4_tx_pc10: uart4_tx_pc10 {
				pinmux = < 0x548 >;
				bias-pull-up;
			};
			uart5_tx_pc12: uart5_tx_pc12 {
				pinmux = < 0x588 >;
				bias-pull-up;
			};
			usart6_tx_pc6: usart6_tx_pc6 {
				pinmux = < 0x4c8 >;
				bias-pull-up;
				phandle = < 0xb >;
			};
			uart7_tx_pe8: uart7_tx_pe8 {
				pinmux = < 0x908 >;
				bias-pull-up;
			};
			uart8_tx_pe1: uart8_tx_pe1 {
				pinmux = < 0x828 >;
				bias-pull-up;
			};
			usb_otg_fs_sof_pa8: usb_otg_fs_sof_pa8 {
				pinmux = < 0x10a >;
			};
			usb_otg_fs_vbus_pa9: usb_otg_fs_vbus_pa9 {
				pinmux = < 0x130 >;
			};
			usb_otg_fs_id_pa10: usb_otg_fs_id_pa10 {
				pinmux = < 0x14a >;
			};
			usb_otg_fs_dm_pa11: usb_otg_fs_dm_pa11 {
				pinmux = < 0x16a >;
				phandle = < 0x13 >;
			};
			usb_otg_fs_dp_pa12: usb_otg_fs_dp_pa12 {
				pinmux = < 0x18a >;
				phandle = < 0x14 >;
			};
			usb_otg_hs_sof_pa4: usb_otg_hs_sof_pa4 {
				pinmux = < 0x8c >;
			};
			usb_otg_hs_id_pb12: usb_otg_hs_id_pb12 {
				pinmux = < 0x38c >;
			};
			usb_otg_hs_vbus_pb13: usb_otg_hs_vbus_pb13 {
				pinmux = < 0x3b0 >;
			};
			usb_otg_hs_dm_pb14: usb_otg_hs_dm_pb14 {
				pinmux = < 0x3cc >;
			};
			usb_otg_hs_dp_pb15: usb_otg_hs_dp_pb15 {
				pinmux = < 0x3ec >;
			};
			usb_otg_hs_ulpi_d0_pa3: usb_otg_hs_ulpi_d0_pa3 {
				pinmux = < 0x6a >;
			};
			usb_otg_hs_ulpi_d1_pb0: usb_otg_hs_ulpi_d1_pb0 {
				pinmux = < 0x20a >;
			};
			usb_otg_hs_ulpi_d2_pb1: usb_otg_hs_ulpi_d2_pb1 {
				pinmux = < 0x22a >;
			};
			usb_otg_hs_ulpi_d7_pb5: usb_otg_hs_ulpi_d7_pb5 {
				pinmux = < 0x2aa >;
			};
			usb_otg_hs_ulpi_d3_pb10: usb_otg_hs_ulpi_d3_pb10 {
				pinmux = < 0x34a >;
			};
			usb_otg_hs_ulpi_d4_pb11: usb_otg_hs_ulpi_d4_pb11 {
				pinmux = < 0x36a >;
			};
			usb_otg_hs_ulpi_d5_pb12: usb_otg_hs_ulpi_d5_pb12 {
				pinmux = < 0x38a >;
			};
			usb_otg_hs_ulpi_d6_pb13: usb_otg_hs_ulpi_d6_pb13 {
				pinmux = < 0x3aa >;
			};
			usb_otg_hs_ulpi_stp_pc0: usb_otg_hs_ulpi_stp_pc0 {
				pinmux = < 0x40a >;
			};
			usb_otg_hs_ulpi_dir_pc2: usb_otg_hs_ulpi_dir_pc2 {
				pinmux = < 0x44a >;
			};
			usb_otg_hs_ulpi_nxt_pc3: usb_otg_hs_ulpi_nxt_pc3 {
				pinmux = < 0x46a >;
			};
		};
		iwdg: watchdog@40003000 {
			compatible = "st,stm32-watchdog";
			reg = < 0x40003000 0x400 >;
			status = "okay";
		};
		wwdg: watchdog@40002c00 {
			compatible = "st,stm32-window-watchdog";
			reg = < 0x40002c00 0x400 >;
			clocks = < &rcc 0x40 0x800 >;
			interrupts = < 0x0 0x7 >;
			status = "disabled";
		};
		usart1: chnl_b_usart: serial@40011000 {
			compatible = "st,stm32-usart", "st,stm32-uart";
			reg = < 0x40011000 0x400 >;
			clocks = < &rcc 0x44 0x10 >;
			resets = < &rctl 0x484 >;
			interrupts = < 0x25 0x0 >;
			status = "okay";
			pinctrl-0 = < &usart1_tx_pb6 &usart1_rx_pb7 >;
			pinctrl-names = "default";
			current-speed = < 0x1c200 >;
		};
		usart2: chnl_a_usart: serial@40004400 {
			compatible = "st,stm32-usart", "st,stm32-uart";
			reg = < 0x40004400 0x400 >;
			clocks = < &rcc 0x40 0x20000 >;
			resets = < &rctl 0x411 >;
			interrupts = < 0x26 0x0 >;
			status = "disabled";
			pinctrl-0 = < &usart2_tx_pd5 &usart2_rx_pd6 &usart2_rts_pd4 &usart2_cts_pd3 >;
			pinctrl-names = "default";
			current-speed = < 0x1c200 >;
		};
		usart6: serial@40011400 {
			compatible = "st,stm32-usart", "st,stm32-uart";
			reg = < 0x40011400 0x400 >;
			clocks = < &rcc 0x44 0x20 >;
			resets = < &rctl 0x485 >;
			interrupts = < 0x47 0x0 >;
			status = "okay";
			pinctrl-0 = < &usart6_tx_pc6 &usart6_rx_pc7 >;
			pinctrl-names = "default";
			current-speed = < 0x1c200 >;
		};
		i2c1: chnl_s: i2c@40005400 {
			compatible = "st,stm32-i2c-v1";
			clock-frequency = < 0x61a80 >;
			#address-cells = < 0x1 >;
			#size-cells = < 0x0 >;
			reg = < 0x40005400 0x400 >;
			clocks = < &rcc 0x40 0x200000 >;
			interrupts = < 0x1f 0x0 >, < 0x20 0x0 >;
			interrupt-names = "event", "error";
			status = "okay";
			pinctrl-0 = < &i2c1_scl_pb8 &i2c1_sda_pb9 >;
			pinctrl-names = "default";
			lm75@48 {
				compatible = "lm75";
				reg = < 0x48 >;
			};
			eeprom: M24256_B@50 {
				status = "disabled";
				compatible = "atmel,at24";
				reg = < 0x50 >;
				size = < 0x8000 >;
				pagesize = < 0x40 >;
				address-width = < 0x10 >;
				timeout = < 0xa >;
			};
		};
		i2c2: i2c@40005800 {
			compatible = "st,stm32-i2c-v1";
			clock-frequency = < 0x186a0 >;
			#address-cells = < 0x1 >;
			#size-cells = < 0x0 >;
			reg = < 0x40005800 0x400 >;
			clocks = < &rcc 0x40 0x400000 >;
			interrupts = < 0x21 0x0 >, < 0x22 0x0 >;
			interrupt-names = "event", "error";
			status = "disabled";
		};
		i2c3: i2c@40005c00 {
			compatible = "st,stm32-i2c-v1";
			clock-frequency = < 0x186a0 >;
			#address-cells = < 0x1 >;
			#size-cells = < 0x0 >;
			reg = < 0x40005c00 0x400 >;
			clocks = < &rcc 0x40 0x800000 >;
			interrupts = < 0x48 0x0 >, < 0x49 0x0 >;
			interrupt-names = "event", "error";
			status = "disabled";
		};
		spi1: spi@40013000 {
			compatible = "st,stm32-spi";
			#address-cells = < 0x1 >;
			#size-cells = < 0x0 >;
			reg = < 0x40013000 0x400 >;
			clocks = < &rcc 0x44 0x1000 >;
			interrupts = < 0x23 0x5 >;
			status = "okay";
			pinctrl-0 = < &spi1_sck_pa5 &spi1_miso_pa6 &spi1_mosi_pa7 >;
			pinctrl-names = "default";
		};
		usbotg_fs: zephyr_udc0: usb@50000000 {
			compatible = "st,stm32-otgfs";
			reg = < 0x50000000 0x40000 >;
			interrupts = < 0x43 0x0 >;
			interrupt-names = "otgfs";
			num-bidir-endpoints = < 0x4 >;
			ram-size = < 0x500 >;
			maximum-speed = "full-speed";
			phys = < &otgfs_phy >;
			clocks = < &rcc 0x34 0x80 >, < &rcc 0x2 0xff >;
			status = "okay";
			pinctrl-0 = < &usb_otg_fs_dm_pa11 &usb_otg_fs_dp_pa12 >;
			pinctrl-names = "default";
		};
		timers1: timers@40010000 {
			compatible = "st,stm32-timers";
			reg = < 0x40010000 0x400 >;
			clocks = < &rcc 0x44 0x1 >;
			resets = < &rctl 0x480 >;
			interrupts = < 0x18 0x0 >, < 0x19 0x0 >, < 0x1a 0x0 >, < 0x1b 0x0 >;
			interrupt-names = "brk", "up", "trgcom", "cc";
			st,prescaler = < 0x0 >;
			status = "disabled";
			pwm {
				compatible = "st,stm32-pwm";
				status = "disabled";
				#pwm-cells = < 0x3 >;
			};
			qdec {
				compatible = "st,stm32-qdec";
				status = "disabled";
				st,input-filter-level = < 0x0 >;
			};
		};
		timers2: timers@40000000 {
			compatible = "st,stm32-timers";
			reg = < 0x40000000 0x400 >;
			clocks = < &rcc 0x40 0x1 >;
			resets = < &rctl 0x400 >;
			interrupts = < 0x1c 0x0 >;
			interrupt-names = "global";
			st,prescaler = < 0x0 >;
			status = "disabled";
			pwm {
				compatible = "st,stm32-pwm";
				status = "disabled";
				#pwm-cells = < 0x3 >;
			};
			counter {
				compatible = "st,stm32-counter";
				status = "disabled";
			};
			qdec {
				compatible = "st,stm32-qdec";
				status = "disabled";
				st,input-filter-level = < 0x0 >;
			};
		};
		timers3: timers@40000400 {
			compatible = "st,stm32-timers";
			reg = < 0x40000400 0x400 >;
			clocks = < &rcc 0x40 0x2 >;
			resets = < &rctl 0x401 >;
			interrupts = < 0x1d 0x0 >;
			interrupt-names = "global";
			st,prescaler = < 0x0 >;
			status = "disabled";
			pwm {
				compatible = "st,stm32-pwm";
				status = "disabled";
				#pwm-cells = < 0x3 >;
			};
			counter {
				compatible = "st,stm32-counter";
				status = "disabled";
			};
			qdec {
				compatible = "st,stm32-qdec";
				status = "disabled";
				st,input-filter-level = < 0x0 >;
			};
		};
		timers4: timers@40000800 {
			compatible = "st,stm32-timers";
			reg = < 0x40000800 0x400 >;
			clocks = < &rcc 0x40 0x4 >;
			resets = < &rctl 0x402 >;
			interrupts = < 0x1e 0x0 >;
			interrupt-names = "global";
			st,prescaler = < 0x0 >;
			status = "disabled";
			pwm {
				compatible = "st,stm32-pwm";
				status = "disabled";
				#pwm-cells = < 0x3 >;
			};
			counter {
				compatible = "st,stm32-counter";
				status = "disabled";
			};
			qdec {
				compatible = "st,stm32-qdec";
				status = "disabled";
				st,input-filter-level = < 0x0 >;
			};
		};
		timers5: timers@40000c00 {
			compatible = "st,stm32-timers";
			reg = < 0x40000c00 0x400 >;
			clocks = < &rcc 0x40 0x8 >;
			resets = < &rctl 0x403 >;
			interrupts = < 0x32 0x0 >;
			interrupt-names = "global";
			st,prescaler = < 0x0 >;
			status = "disabled";
			pwm {
				compatible = "st,stm32-pwm";
				status = "disabled";
				#pwm-cells = < 0x3 >;
			};
			counter {
				compatible = "st,stm32-counter";
				status = "disabled";
			};
			qdec {
				compatible = "st,stm32-qdec";
				status = "disabled";
				st,input-filter-level = < 0x0 >;
			};
		};
		timers9: timers@40014000 {
			compatible = "st,stm32-timers";
			reg = < 0x40014000 0x400 >;
			clocks = < &rcc 0x44 0x10000 >;
			resets = < &rctl 0x490 >;
			interrupts = < 0x18 0x0 >;
			interrupt-names = "global";
			st,prescaler = < 0x0 >;
			status = "disabled";
			pwm {
				compatible = "st,stm32-pwm";
				status = "disabled";
				#pwm-cells = < 0x3 >;
			};
			counter {
				compatible = "st,stm32-counter";
				status = "disabled";
			};
		};
		timers10: timers@40014400 {
			compatible = "st,stm32-timers";
			reg = < 0x40014400 0x400 >;
			clocks = < &rcc 0x44 0x20000 >;
			resets = < &rctl 0x491 >;
			interrupts = < 0x19 0x0 >;
			interrupt-names = "global";
			st,prescaler = < 0x0 >;
			status = "disabled";
			pwm {
				compatible = "st,stm32-pwm";
				status = "disabled";
				#pwm-cells = < 0x3 >;
			};
			counter {
				compatible = "st,stm32-counter";
				status = "disabled";
			};
		};
		timers11: timers@40014800 {
			compatible = "st,stm32-timers";
			reg = < 0x40014800 0x400 >;
			clocks = < &rcc 0x44 0x40000 >;
			resets = < &rctl 0x492 >;
			interrupts = < 0x1a 0x0 >;
			interrupt-names = "global";
			st,prescaler = < 0x0 >;
			status = "disabled";
			pwm {
				compatible = "st,stm32-pwm";
				status = "disabled";
				#pwm-cells = < 0x3 >;
			};
			counter {
				compatible = "st,stm32-counter";
				status = "disabled";
			};
		};
		rtc: rtc@40002800 {
			compatible = "st,stm32-rtc";
			reg = < 0x40002800 0x400 >;
			interrupts = < 0x29 0x0 >;
			clocks = < &rcc 0x40 0x10000000 >;
			prescaler = < 0x8000 >;
			status = "okay";
			bbram: backup_regs {
				compatible = "st,stm32-bbram";
				st,backup-regs = < 0x14 >;
				status = "disabled";
			};
		};
		adc1: adc@40012000 {
			compatible = "st,stm32f4-adc", "st,stm32-adc";
			reg = < 0x40012000 0x400 >;
			clocks = < &rcc 0x44 0x100 >;
			interrupts = < 0x12 0x0 >;
			status = "disabled";
			#io-channel-cells = < 0x1 >;
			resolutions = < 0x607804 0x517804 0x427804 0x337804 >;
			sampling-times = < 0x3 0xf 0x1c 0x38 0x54 0x70 0x90 0x1e0 >;
			st,adc-clock-source = < 0x1 >;
			st,adc-sequencer = < 0x1 >;
			phandle = < 0x30 >;
		};
		dma1: dma@40026000 {
			compatible = "st,stm32-dma-v1";
			#dma-cells = < 0x4 >;
			reg = < 0x40026000 0x400 >;
			interrupts = < 0xb 0x0 0xc 0x0 0xd 0x0 0xe 0x0 0xf 0x0 0x10 0x0 0x11 0x0 0x2f 0x0 >;
			clocks = < &rcc 0x30 0x200000 >;
			status = "okay";
			phandle = < 0x1c >;
		};
		dma2: dma@40026400 {
			compatible = "st,stm32-dma-v1";
			#dma-cells = < 0x4 >;
			reg = < 0x40026400 0x400 >;
			interrupts = < 0x38 0x0 0x39 0x0 0x3a 0x0 0x3b 0x0 0x3c 0x0 0x44 0x0 0x45 0x0 0x46 0x0 >;
			clocks = < &rcc 0x30 0x400000 >;
			st,mem2mem;
			status = "okay";
		};
		sdmmc1: sdmmc@40012c00 {
			compatible = "st,stm32-sdmmc";
			reg = < 0x40012c00 0x400 >;
			clocks = < &rcc 0x44 0x800 >, < &rcc 0x2 0xff >;
			resets = < &rctl 0x48b >;
			interrupts = < 0x31 0x0 >;
			status = "disabled";
		};
		spi2: spi@40003800 {
			compatible = "st,stm32-spi";
			#address-cells = < 0x1 >;
			#size-cells = < 0x0 >;
			reg = < 0x40003800 0x400 >;
			clocks = < &rcc 0x40 0x4000 >;
			interrupts = < 0x24 0x5 >;
			status = "okay";
			pinctrl-0 = < &spi2_sck_pb10 &spi2_miso_pb14 &spi2_mosi_pb15 >;
			pinctrl-names = "default";
			cs-gpios = < &gpioe 0x6 0x1 >, < &gpioe 0x5 0x1 >;
			sdhc0: sdhc@0 {
				compatible = "zephyr,sdhc-spi-slot";
				reg = < 0x0 >;
				status = "okay";
				spi-max-frequency = < 0x1312d00 >;
				mmc {
					compatible = "zephyr,sdmmc-disk";
					status = "okay";
				};
			};
			mx25l128: mx25l12835f@1 {
				compatible = "jedec,spi-nor";
				reg = < 0x1 >;
				size = < 0x1000000 >;
				spi-max-frequency = < 0x7ed6b40 >;
				jedec-id = [ C2 20 18 ];
				status = "okay";
				reset-gpios = < &gpioe 0x0 0x1 >;
				partitions {
					compatible = "fixed-partitions";
					#address-cells = < 0x1 >;
					#size-cells = < 0x1 >;
					scratch_partition: partition@0 {
						label = "image-scratch";
						reg = < 0x0 0x20000 >;
					};
					settings_partition: partition@20000 {
						label = "settings";
						reg = < 0x20000 0x710000 >;
					};
					storage_partition: partition@730000 {
						label = "storage";
						reg = < 0x730000 0x710000 >;
					};
					slot1_partition: partition@E40000 {
						label = "image-1";
						reg = < 0xe40000 0x1c0000 >;
					};
				};
			};
		};
		spi3: chnl_c_spi: spi@40003c00 {
			compatible = "st,stm32-spi";
			#address-cells = < 0x1 >;
			#size-cells = < 0x0 >;
			reg = < 0x40003c00 0x400 >;
			clocks = < &rcc 0x40 0x8000 >;
			interrupts = < 0x33 0x5 >;
			status = "okay";
			pinctrl-0 = < &spi3_sck_pc10 &spi3_miso_pc11 &spi3_mosi_pc12 >;
			pinctrl-names = "default";
			dmas = < &dma1 0x5 0x0 0x28440 0x3 >, < &dma1 0x2 0x0 0x28480 0x3 >;
			dma-names = "tx", "rx";
			cs-gpios = < &gpiod 0xb 0x1 >;
			spi_cc1200: cc1200@0 {
				compatible = "ti,cc1200";
				cca-gpios = < &gpiod 0xb 0x1 >;
				reg = < 0x0 >;
				spi-max-frequency = < 0x1e8480 >;
				int-gpios = < &gpiob 0x5 0x0 >;
				status = "okay";
			};
		};
		spi4: spi@40013400 {
			compatible = "st,stm32-spi";
			#address-cells = < 0x1 >;
			#size-cells = < 0x0 >;
			reg = < 0x40013400 0x400 >;
			clocks = < &rcc 0x44 0x2000 >;
			interrupts = < 0x54 0x5 >;
			status = "disabled";
		};
		i2s2: i2s@40003800 {
			compatible = "st,stm32-i2s";
			#address-cells = < 0x1 >;
			#size-cells = < 0x0 >;
			reg = < 0x40003800 0x400 >;
			clocks = < &rcc 0x40 0x4000 >;
			interrupts = < 0x24 0x5 >;
			dmas = < &dma1 0x4 0x0 0x400 0x3 &dma1 0x3 0x0 0x400 0x3 >;
			dma-names = "tx", "rx";
			status = "disabled";
		};
		i2s3: i2s@40003c00 {
			compatible = "st,stm32-i2s";
			#address-cells = < 0x1 >;
			#size-cells = < 0x0 >;
			reg = < 0x40003c00 0x400 >;
			clocks = < &rcc 0x40 0x8000 >;
			interrupts = < 0x33 0x5 >;
			dmas = < &dma1 0x5 0x0 0x400 0x3 &dma1 0x0 0x0 0x400 0x3 >;
			dma-names = "tx", "rx";
			status = "disabled";
		};
		usart3: chnl_c_usart: serial@40004800 {
			compatible = "st,stm32-usart", "st,stm32-uart";
			reg = < 0x40004800 0x400 >;
			clocks = < &rcc 0x40 0x40000 >;
			resets = < &rctl 0x412 >;
			interrupts = < 0x27 0x0 >;
			status = "disabled";
			pinctrl-0 = < &usart3_tx_pd8 &usart3_rx_pd9 &usart3_rts_pd12 &usart3_cts_pd11 >;
			pinctrl-names = "default";
			current-speed = < 0x1c200 >;
		};
		uart4: serial@40004c00 {
			compatible = "st,stm32-uart";
			reg = < 0x40004c00 0x400 >;
			clocks = < &rcc 0x40 0x80000 >;
			resets = < &rctl 0x413 >;
			interrupts = < 0x34 0x0 >;
			status = "disabled";
		};
		uart5: serial@40005000 {
			compatible = "st,stm32-uart";
			reg = < 0x40005000 0x400 >;
			clocks = < &rcc 0x40 0x100000 >;
			resets = < &rctl 0x414 >;
			interrupts = < 0x35 0x0 >;
			status = "disabled";
		};
		timers6: timers@40001000 {
			compatible = "st,stm32-timers";
			reg = < 0x40001000 0x400 >;
			clocks = < &rcc 0x40 0x10 >;
			resets = < &rctl 0x404 >;
			interrupts = < 0x36 0x0 >;
			interrupt-names = "global";
			st,prescaler = < 0x0 >;
			status = "disabled";
			counter {
				compatible = "st,stm32-counter";
				status = "disabled";
			};
		};
		timers7: timers@40001400 {
			compatible = "st,stm32-timers";
			reg = < 0x40001400 0x400 >;
			clocks = < &rcc 0x40 0x20 >;
			resets = < &rctl 0x405 >;
			interrupts = < 0x37 0x0 >;
			interrupt-names = "global";
			st,prescaler = < 0x0 >;
			status = "disabled";
			counter {
				compatible = "st,stm32-counter";
				status = "disabled";
			};
		};
		timers8: timers@40010400 {
			compatible = "st,stm32-timers";
			reg = < 0x40010400 0x400 >;
			clocks = < &rcc 0x44 0x2 >;
			resets = < &rctl 0x481 >;
			interrupts = < 0x2b 0x0 >, < 0x2c 0x0 >, < 0x2d 0x0 >, < 0x2e 0x0 >;
			interrupt-names = "brk", "up", "trgcom", "cc";
			st,prescaler = < 0x0 >;
			status = "disabled";
			pwm {
				compatible = "st,stm32-pwm";
				status = "disabled";
				#pwm-cells = < 0x3 >;
			};
			qdec {
				compatible = "st,stm32-qdec";
				status = "disabled";
				st,input-filter-level = < 0x0 >;
			};
		};
		timers12: timers@40001800 {
			compatible = "st,stm32-timers";
			reg = < 0x40001800 0x400 >;
			clocks = < &rcc 0x40 0x40 >;
			resets = < &rctl 0x406 >;
			interrupts = < 0x2b 0x0 >;
			interrupt-names = "global";
			st,prescaler = < 0x0 >;
			status = "disabled";
			pwm {
				compatible = "st,stm32-pwm";
				status = "disabled";
				#pwm-cells = < 0x3 >;
			};
			counter {
				compatible = "st,stm32-counter";
				status = "disabled";
			};
		};
		timers13: timers@40001c00 {
			compatible = "st,stm32-timers";
			reg = < 0x40001c00 0x400 >;
			clocks = < &rcc 0x40 0x80 >;
			resets = < &rctl 0x407 >;
			interrupts = < 0x2c 0x0 >;
			interrupt-names = "global";
			st,prescaler = < 0x0 >;
			status = "disabled";
			pwm {
				compatible = "st,stm32-pwm";
				status = "disabled";
				#pwm-cells = < 0x3 >;
			};
			counter {
				compatible = "st,stm32-counter";
				status = "disabled";
			};
		};
		timers14: timers@40002000 {
			compatible = "st,stm32-timers";
			reg = < 0x40002000 0x400 >;
			clocks = < &rcc 0x40 0x100 >;
			resets = < &rctl 0x408 >;
			interrupts = < 0x2d 0x0 >;
			interrupt-names = "global";
			st,prescaler = < 0x0 >;
			status = "disabled";
			pwm {
				compatible = "st,stm32-pwm";
				status = "disabled";
				#pwm-cells = < 0x3 >;
			};
			counter {
				compatible = "st,stm32-counter";
				status = "disabled";
			};
		};
		usbotg_hs: usb@40040000 {
			compatible = "st,stm32-otghs";
			reg = < 0x40040000 0x40000 >;
			interrupts = < 0x4d 0x0 >, < 0x4a 0x0 >, < 0x4b 0x0 >;
			interrupt-names = "otghs", "ep1_out", "ep1_in";
			num-bidir-endpoints = < 0x6 >;
			ram-size = < 0x1000 >;
			maximum-speed = "full-speed";
			phys = < &otghs_fs_phy >;
			clocks = < &rcc 0x30 0x20000000 >, < &rcc 0x2 0xff >;
			status = "disabled";
		};
		can1: chnl_a_can: can@40006400 {
			compatible = "st,stm32-bxcan";
			reg = < 0x40006400 0x400 >;
			interrupts = < 0x13 0x0 >, < 0x14 0x0 >, < 0x15 0x0 >, < 0x16 0x0 >;
			interrupt-names = "TX", "RX0", "RX1", "SCE";
			clocks = < &rcc 0x40 0x2000000 >;
			status = "disabled";
			sample-point = < 0x36b >;
			pinctrl-0 = < &can1_rx_pd0 &can1_tx_pd1 >;
			pinctrl-names = "default";
			bus-speed = < 0x1e848 >;
		};
		can2: can@40006800 {
			compatible = "st,stm32-bxcan";
			reg = < 0x40006800 0x400 >;
			interrupts = < 0x3f 0x0 >, < 0x40 0x0 >, < 0x41 0x0 >, < 0x42 0x0 >;
			interrupt-names = "TX", "RX0", "RX1", "SCE";
			clocks = < &rcc 0x40 0x6000000 >;
			master-can-reg = < 0x40006400 >;
			status = "disabled";
			sample-point = < 0x36b >;
		};
		rng: rng@50060800 {
			compatible = "st,stm32-rng";
			reg = < 0x50060800 0x400 >;
			interrupts = < 0x50 0x0 >;
			clocks = < &rcc 0x34 0x40 >;
			status = "okay";
		};
		backup_sram: memory@40024000 {
			compatible = "zephyr,memory-region", "st,stm32-backup-sram";
			reg = < 0x40024000 0x1000 >;
			clocks = < &rcc 0x30 0x40000 >;
			zephyr,memory-region = "BACKUP_SRAM";
			status = "disabled";
		};
		adc2: adc@40012100 {
			compatible = "st,stm32-adc";
			reg = < 0x40012100 0x50 >;
			clocks = < &rcc 0x44 0x200 >;
			interrupts = < 0x12 0x0 >;
			status = "disabled";
			#io-channel-cells = < 0x1 >;
			resolutions = < 0x607804 0x517804 0x427804 0x337804 >;
			sampling-times = < 0x3 0xf 0x1c 0x38 0x54 0x70 0x90 0x1e0 >;
			st,adc-clock-source = < 0x1 >;
			st,adc-sequencer = < 0x1 >;
		};
		adc3: adc@40012200 {
			compatible = "st,stm32-adc";
			reg = < 0x40012200 0x50 >;
			clocks = < &rcc 0x44 0x400 >;
			interrupts = < 0x12 0x0 >;
			status = "disabled";
			#io-channel-cells = < 0x1 >;
			resolutions = < 0x607804 0x517804 0x427804 0x337804 >;
			sampling-times = < 0x3 0xf 0x1c 0x38 0x54 0x70 0x90 0x1e0 >;
			st,adc-clock-source = < 0x1 >;
			st,adc-sequencer = < 0x1 >;
		};
		dac1: dac@40007400 {
			compatible = "st,stm32-dac";
			reg = < 0x40007400 0x400 >;
			clocks = < &rcc 0x40 0x20000000 >;
			status = "disabled";
			#io-channel-cells = < 0x1 >;
		};
		mac: ethernet@40028000 {
			compatible = "st,stm32-ethernet";
			reg = < 0x40028000 0x8000 >;
			interrupts = < 0x3d 0x0 >;
			clock-names = "stmmaceth", "mac-clk-tx", "mac-clk-rx", "mac-clk-ptp";
			clocks = < &rcc 0x30 0x2000000 >, < &rcc 0x30 0x4000000 >, < &rcc 0x30 0x8000000 >, < &rcc 0x30 0x10000000 >;
			status = "okay";
			pinctrl-0 = < &eth_mdc_pc1 &eth_rxd0_pc4 &eth_rxd1_pc5 &eth_ref_clk_pa1 &eth_mdio_pa2 &eth_crs_dv_pa7 &eth_tx_en_pb11 &eth_txd0_pb12 &eth_txd1_pb13 >;
			pinctrl-names = "default";
		};
		uart7: serial@40007800 {
			compatible = "st,stm32-uart";
			reg = < 0x40007800 0x400 >;
			clocks = < &rcc 0x40 0x40000000 >;
			resets = < &rctl 0x41e >;
			interrupts = < 0x52 0x0 >;
			status = "disabled";
		};
		uart8: serial@40007c00 {
			compatible = "st,stm32-uart";
			reg = < 0x40007c00 0x400 >;
			clocks = < &rcc 0x40 0x80000000 >;
			resets = < &rctl 0x41f >;
			interrupts = < 0x53 0x0 >;
			status = "disabled";
		};
		fmc: memory-controller@a0000000 {
			compatible = "st,stm32-fmc";
			reg = < 0xa0000000 0x400 >;
			clocks = < &rcc 0x38 0x1 >;
			status = "disabled";
			sdram: sdram {
				compatible = "st,stm32-fmc-sdram";
				#address-cells = < 0x1 >;
				#size-cells = < 0x0 >;
				status = "disabled";
			};
		};
	};
	cpus {
		#address-cells = < 0x1 >;
		#size-cells = < 0x0 >;
		cpu@0 {
			device_type = "cpu";
			compatible = "arm,cortex-m4f";
			reg = < 0x0 >;
		};
	};
	sram0: memory@20000000 {
		compatible = "mmio-sram";
		reg = < 0x20000000 0x30000 >;
	};
	clocks {
		clk_hse: clk-hse {
			#clock-cells = < 0x0 >;
			compatible = "st,stm32-hse-clock";
			status = "okay";
			clock-frequency = < 0x17d7840 >;
			phandle = < 0x2f >;
		};
		clk_hsi: clk-hsi {
			#clock-cells = < 0x0 >;
			compatible = "fixed-clock";
			clock-frequency = < 0xf42400 >;
			status = "disabled";
		};
		clk_lse: clk-lse {
			#clock-cells = < 0x0 >;
			compatible = "fixed-clock";
			clock-frequency = < 0x8000 >;
			status = "disabled";
		};
		clk_lsi: clk-lsi {
			#clock-cells = < 0x0 >;
			compatible = "fixed-clock";
			clock-frequency = < 0x7d00 >;
			status = "disabled";
		};
		pll: pll {
			#clock-cells = < 0x0 >;
			compatible = "st,stm32f4-pll-clock";
			status = "okay";
			div-m = < 0x19 >;
			mul-n = < 0x150 >;
			div-p = < 0x2 >;
			div-q = < 0x7 >;
			clocks = < &clk_hse >;
			phandle = < 0x2 >;
		};
		plli2s: plli2s {
			#clock-cells = < 0x0 >;
			compatible = "st,stm32f4-plli2s-clock";
			status = "disabled";
		};
	};
	die_temp: dietemp {
		compatible = "st,stm32-temp-cal";
		ts-cal1-addr = < 0x1fff7a2c >;
		ts-cal2-addr = < 0x1fff7a2e >;
		ts-cal1-temp = < 0x1e >;
		ts-cal2-temp = < 0x6e >;
		ts-cal-vrefanalog = < 0xce4 >;
		io-channels = < &adc1 0x12 >;
		status = "disabled";
	};
	vref: vref {
		compatible = "st,stm32-vref";
		vrefint-cal-addr = < 0x1fff7a2a >;
		vrefint-cal-mv = < 0xce4 >;
		io-channels = < &adc1 0x11 >;
		status = "disabled";
	};
	vbat: vbat {
		compatible = "st,stm32-vbat";
		ratio = < 0x4 >;
		io-channels = < &adc1 0x12 >;
		status = "disabled";
	};
	otgfs_phy: otgfs_phy {
		compatible = "usb-nop-xceiv";
		#phy-cells = < 0x0 >;
		phandle = < 0x12 >;
	};
	otghs_fs_phy: otghs_fs_phy {
		compatible = "usb-nop-xceiv";
		#phy-cells = < 0x0 >;
		phandle = < 0x23 >;
	};
	ccm0: memory@10000000 {
		compatible = "zephyr,memory-region", "st,stm32-ccm";
		reg = < 0x10000000 0x10000 >;
		zephyr,memory-region = "CCM";
	};
	bb_header: connector {
		compatible = "lmt,bb-header";
		#gpio-cells = < 0x2 >;
		gpio-map-mask = < 0xffffffff 0xffffffc0 >;
		gpio-map-pass-thru = < 0x0 0x3f >;
		gpio-map = < 0x5 0x0 &gpiob 0x8 0x0 >, < 0x6 0x0 &gpiob 0x9 0x0 >, < 0x7 0x0 &gpiob 0x5 0x0 >, < 0x8 0x0 &gpiod 0x7 0x0 >, < 0x9 0x0 &gpiod 0x5 0x0 >, < 0xa 0x0 &gpiod 0x6 0x0 >, < 0xb 0x0 &gpiod 0x4 0x0 >, < 0xc 0x0 &gpiod 0x3 0x0 >, < 0xd 0x0 &gpiob 0x6 0x0 >, < 0xe 0x0 &gpiob 0x7 0x0 >, < 0xf 0x0 &gpioe 0x3 0x0 >, < 0x10 0x0 &gpioe 0x4 0x0 >, < 0x13 0x0 &gpioc 0xc 0x0 >, < 0x14 0x0 &gpioc 0xb 0x0 >, < 0x15 0x0 &gpioc 0xa 0x0 >, < 0x16 0x0 &gpioa 0x4 0x0 >, < 0x17 0x0 &gpioe 0x8 0x0 >, < 0x18 0x0 &gpioe 0xa 0x0 >, < 0x19 0x0 &gpioe 0xc 0x0 >, < 0x1a 0x0 &gpioe 0xf 0x0 >, < 0x1b 0x0 &gpioe 0x9 0x0 >, < 0x1c 0x0 &gpioe 0xb 0x0 >, < 0x1d 0x0 &gpioe 0xd 0x0 >, < 0x1e 0x0 &gpioe 0xe 0x0 >;
	};
	leds {
		compatible = "gpio-leds";
		glc_led: led_1 {
			gpios = < &gpiod 0xd 0x0 >;
			label = "Green Light Cathode";
		};
		yarc_led: led_2 {
			gpios = < &gpiod 0xe 0x0 >, < &gpiod 0xf 0x1 >;
			label = "Yellow Annode Red Cathode";
		};
		ycra_led: led_3 {
			gpios = < &gpiod 0xf 0x0 >, < &gpiod 0xe 0x1 >;
			label = "Yellow Cathode Red Annode";
		};
	};
	gpio_keys {
		compatible = "gpio-keys";
		user_button: button {
			label = "User";
			gpios = < &gpioc 0xf 0x1 >;
		};
	};
};
